# MDR1923VK014 register map
Vendor: Milandr; Series: ARMCM0; File version: 2.0
ARM 32-bit Cortex-M0 Microcontroller based device, CPU clock up to 50MHz, etc.
CPU: CM0 r0p0, little endian, no MPU, no FPU, 3 interrupt priority bits
Registers are 32-bit, read-write, reset 0x0 unless marked. A register's access mark holds for its fields unless they carry their own. Offsets are from the block's base; lines under a group give offsets from that group; [hi:lo] are bit positions; {n}, {i} and the like mark numbered series; 'fields as' and 'values as' point back to an identical list; <NAME> marks a mode.

## Memory map
0x40000000 MDR_RST_CLOCK size 0x1D0 — CLock Control
0x40001000 MDR_BKP size 0x184 — Backup and RTC Control
0x40080000 MDR_PORTA size 0x8C — PORTA
0x40081000 MDR_PORTB size 0x8C — PORTB
0x40082000 MDR_PORTC size 0x8C — PORTC
0x40083000 MDR_PORTD size 0x8C — PORTD
0x40084000 MDR_PORTE size 0x8C — PORTE
0x4008A000 MDR_TIMER1 size 0x90 — TIMER Control
0x4008B000 MDR_TIMER2 size 0x90
0x4008C000 MDR_TIMER3 size 0x90
0x4008D000 MDR_TIMER4 size 0x90
0x4008E000 MDR_TIMER5 size 0x90
0x4008F000 MDR_TIMER6 size 0x90
0x40090000 MDR_CAN1 size 0x600 — CAN Control
0x40091000 MDR_CAN2 size 0x600
0x40095000 MDR_SSP1 size 0x28 — Synchronous Serial Port
0x40096000 MDR_SSP2 size 0x28
0x40097000 MDR_SSP3 size 0x28
0x40098000 MDR_SSP4 size 0x28
0x40099000 MDR_UART1 size 0x84 — UART Control
0x4009A000 MDR_UART2 size 0x84
0x400B1000 MDR_SSP5 size 0x28
0x400B2000 MDR_SSP6 size 0x28
0xE0042000 MDR_DMA size 0x70 — DMA Controler

## MDR_DMA — DMA Controler
Base 0xE0042000
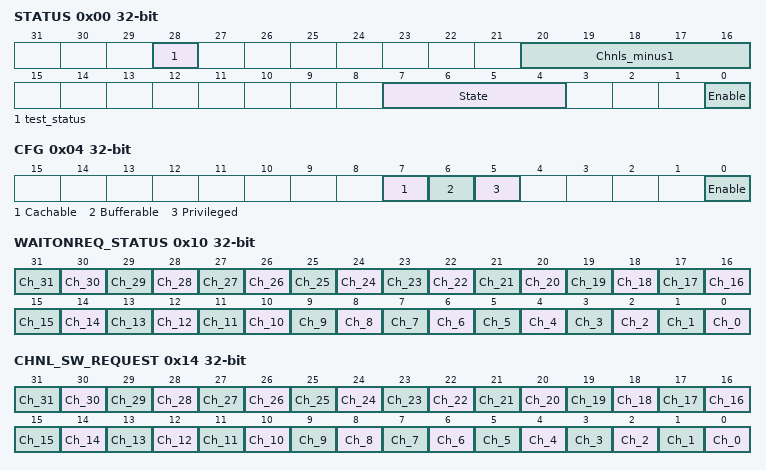
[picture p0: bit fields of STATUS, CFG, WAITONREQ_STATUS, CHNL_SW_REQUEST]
0x00 STATUS ro (reset mask 0xF01F0F01)
  [28] test_status — Test logic availability
    0=Unavailable (Test logic unavailable); 1=Available (Test logic available)
  [20:16] Chnls_minus1 — Channels count
    {v}={v+1}_channels (Channels Count) (v=0..31)
  [7:4] State — Active Operation
    0=Idle state; 1=RD_Ctrl (Reading channel controller data); 2=RD_pSrc (Reading source data end pointer); 3=RD_pDest (Reading destination data end pointer); 4=RD_Data (Reading source data); 5=WR_Data (writing destination data); 6=Wait_Clr (Waiting for DMA request to clear); 7=WR_Ctrl (Writing channel controller data); 8=Stalled transfer; 9=Done transfer; 10=ScatGath (scatter-gather transition)
  [0] Enable — Enable block
    0=Disabled (Block inactive); 1=Enabled (Block active)
0x04 CFG wo — Config register
  [7] Cachable — Cachable AHB bus priority
    0=Off (Inactive); 1=On (Active)
  [6] Bufferable — Bufferable AHB bus priority
    0=Off (Inactive); 1=On (Active)
  [5] Privileged — Privileged AHB bus priority
    0=Off (Inactive); 1=On (Active)
  [0] Enable — Enable block
    0=Disabled (Block inactive); 1=Enabled (Block active)
0x08 CTRL_BASE_PTR — Channel control data base pointer
  [31:10] Addr_Hi — Pointer
0x0C ALT_CTRL_BASE_PTR ro (reset mask 0xFFFFFC00) — Channel alternate control data base pointer
  [31:0] Addr — Pointer
0x10 WAITONREQ_STATUS ro — Channel wait on request status
  [n] Ch_{n} (n=0..31) — Channel Select
    0=Off (Inactive); 1=On (Active)
0x14 CHNL_SW_REQUEST wo write-1-sets — Channel Software Request
  fields as WAITONREQ_STATUS
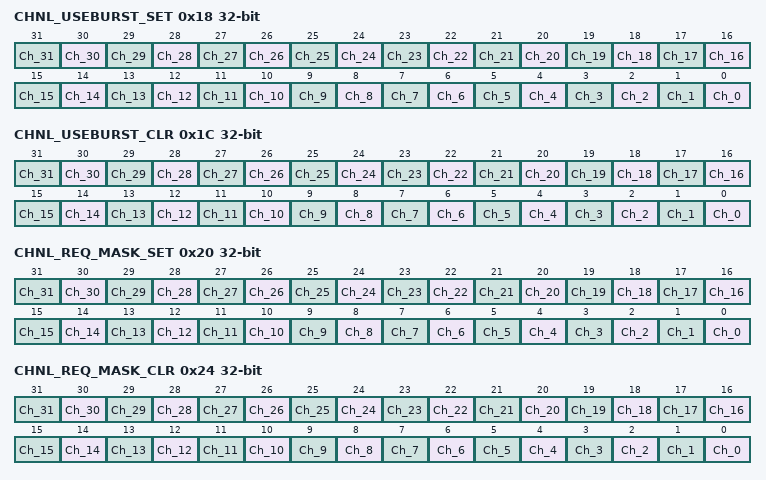
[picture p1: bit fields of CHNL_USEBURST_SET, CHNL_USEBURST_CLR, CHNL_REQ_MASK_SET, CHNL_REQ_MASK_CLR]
0x18 CHNL_USEBURST_SET write-1-sets — Disable SREQ requests
  fields as WAITONREQ_STATUS
0x1C CHNL_USEBURST_CLR wo write-1-clears — Enable SREQ requests
  fields as WAITONREQ_STATUS
0x20 CHNL_REQ_MASK_SET write-1-sets — Disable channel processing
  fields as WAITONREQ_STATUS
0x24 CHNL_REQ_MASK_CLR wo write-1-clears — Enable channel processing
  fields as WAITONREQ_STATUS
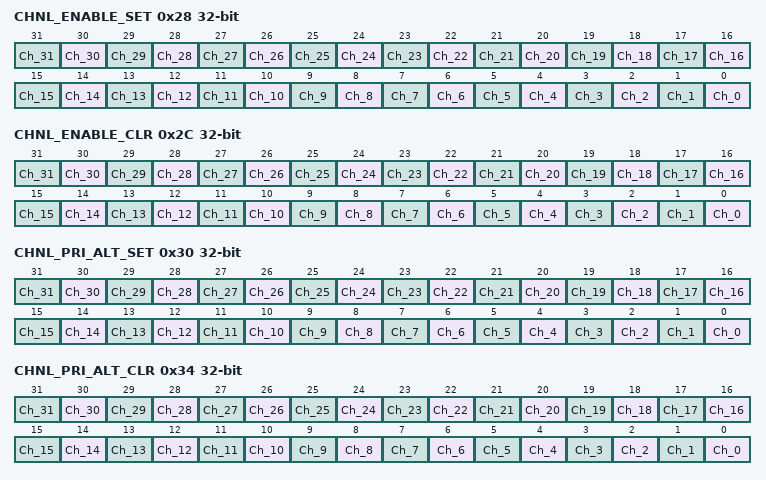
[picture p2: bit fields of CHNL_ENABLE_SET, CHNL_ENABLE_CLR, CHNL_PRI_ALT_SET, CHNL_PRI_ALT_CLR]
0x28 CHNL_ENABLE_SET write-1-sets — Start Channel
  fields as WAITONREQ_STATUS
0x2C CHNL_ENABLE_CLR wo write-1-clears — Stop Channel
  fields as WAITONREQ_STATUS
0x30 CHNL_PRI_ALT_SET write-1-sets — Select Alter Structure
  fields as WAITONREQ_STATUS
0x34 CHNL_PRI_ALT_CLR wo write-1-clears — Select Primary Structure
  fields as WAITONREQ_STATUS
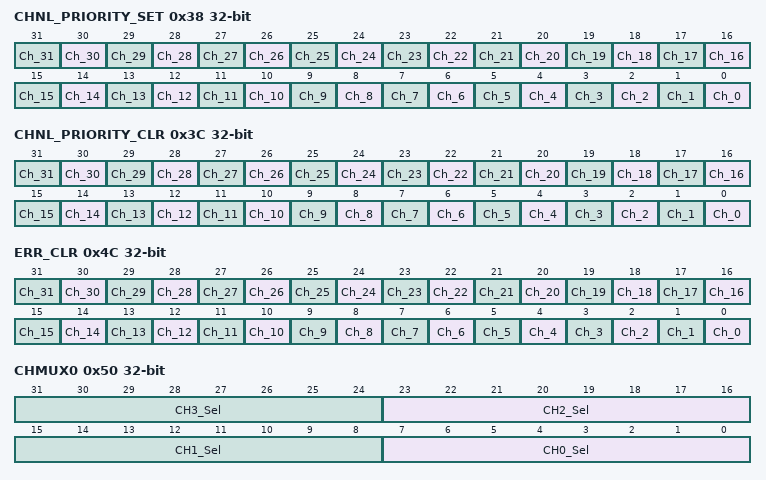
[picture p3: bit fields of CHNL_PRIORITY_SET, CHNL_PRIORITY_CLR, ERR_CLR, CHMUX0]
0x38 CHNL_PRIORITY_SET write-1-sets — Rise up priority to High
  fields as WAITONREQ_STATUS
0x3C CHNL_PRIORITY_CLR wo write-1-clears — Clear Priority to Normal
  fields as WAITONREQ_STATUS
0x4C ERR_CLR write-1-clears — AHB-Lite bus error clear
  fields as WAITONREQ_STATUS
0x50 CHMUX0 — Periph select for DMA channels 0..3
  [8n+7:8n] CH{n}_Sel (n=0..3) — Periph Event for DMA_Channel
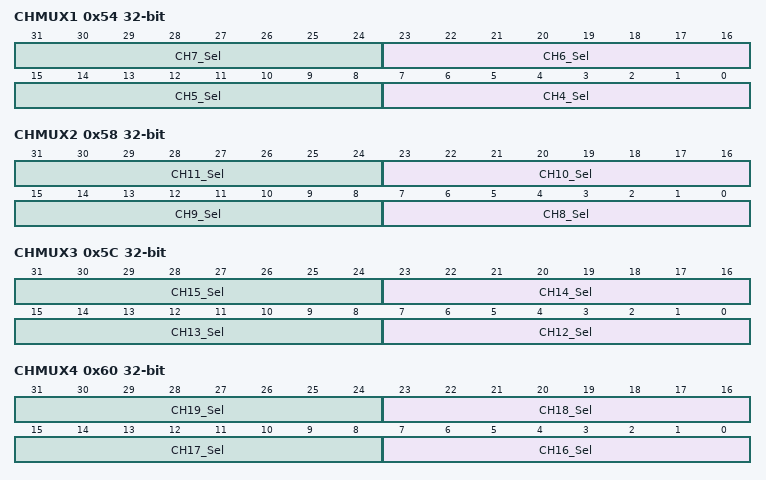
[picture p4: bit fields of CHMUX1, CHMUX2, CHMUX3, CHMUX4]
0x54 CHMUX1 — Periph select for DMA channels 4..7
  [8n-25:8n-32] CH{n}_Sel (n=4..7) — Periph Event for DMA_Channel
0x58 CHMUX2 — Periph select for DMA channels 8..11
  [8n-57:8n-64] CH{n}_Sel (n=8..11) — Periph Event for DMA_Channel
0x5C CHMUX3 — Periph select for DMA channels 12..15
  [8n-89:8n-96] CH{n}_Sel (n=12..15) — Periph Event for DMA_Channel
0x60 CHMUX4 — Periph select for DMA channels 16..19
  [8n-121:8n-128] CH{n}_Sel (n=16..19) — Periph Event for DMA_Channel
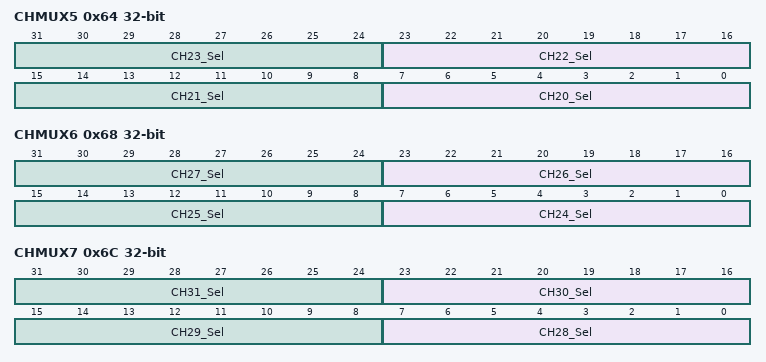
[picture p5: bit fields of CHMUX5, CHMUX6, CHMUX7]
0x64 CHMUX5 — Periph select for DMA channels 20..23
  [8n-153:8n-160] CH{n}_Sel (n=20..23) — Periph Event for DMA_Channel
0x68 CHMUX6 — Periph select for DMA channels 24..27
  [8n-185:8n-192] CH{n}_Sel (n=24..27) — Periph Event for DMA_Channel
0x6C CHMUX7 — Periph select for DMA channels 28..31
  [8n-217:8n-224] CH{n}_Sel (n=28..31) — Periph Event for DMA_Channel
